# EOS-S3 register map
File version: 0.1
CPU: CM4 r0p1, selectable endian, MPU, FPU, 3 interrupt priority bits
Registers are 32-bit, read-write, reset 0x0 unless marked. A register's access mark holds for its fields unless they carry their own. Offsets are from the block's base; [hi:lo] are bit positions; {n}, {i} and the like mark numbered series.

## I2S_Slave
Base 0x4000B000
0x00 IER — I2S Enable Register
  [0] IEN — DW_apb_i2s_enable. A disable on this bit overrides any other block or channel enables and flushes all FIFOs.
    0=disable (Enable DW_APB_I2S.); 1=enable (Disable DW_APB_I2S.)
0x08 ITER — I2S Transmitter Block Enable Register
  [0] TXEN — Transmitter block enable. A disable on this bit overrides any individual transmit channel enables.
    0=Disable the transmitter; 1=Enable the transmitter
0x18 TXFFR — Transmitter Block FIFO Reset Register
  [0] TXFFR wo — Transmitter FIFO Reset. Writing a 1 to this register flushes all the TX FIFOs (this is a self clearing bit). The Transmitter Block must be disabled prior to writing this bit.
0x20 LTHR0 — Left Transmit Holding Register
  [31:0] LTHR0 wo — The left stereo data to be transmitted serially through the transmit channel output (sdox) is written through this register. Writing is a two-stage process: (1) A write to this register passes the left stereo sample to the transmitter. (2) This MUST be followed by writing the right stereo sample to the RTHRx register. Data should only be written to the FIFO when it is not full. Any attempt to write to a full FIFO results in that data being lost and an overrun interrupt being generated.
0x24 RTHR0 — Right Transmit Holding Register
  [31:0] RTHR0 wo — The right stereo data to be transmitted serially through the transmit channel output (sdox) is written through this register. Writing is a two-stage process: (1) A left stereo sample MUST first be written to the LTHRx register. (2) A write to this register passes the right stereo sample to the transmitter. Data should only be written to the FIFO when it is not full. Any attempt to write to a full FIFO results in that data being lost and an overrun interrupt being generated.
0x2C TER0 reset 0x1 — Transmit Enable Register
  [0] TXCHEN0 — Transmit channel enable. This bit enables/disables a transmit channel, independently of all other channels. On enable, the channel begins transmitting on the next left stereo cycle. A global disable of DW_apb_i2s (IER[0] = 0) or Transmitter block (ITER[0] =0) overrides this value.
    0=Disable the transmit channel; 1=Enable the transmit channel
0x34 TCR0 reset 0x2 — Transmit Configuration Register
  [2:0] WLEN — These bits are used to program the data resolution of the transmitter and ensures the MSB of the data is transmitted first. Programmed resolution must be less than or equal to `I2S_TX_WORDSIZE_x`. If the selected resolution is greater than `I2S_TX_WORDSIZE_x`, the transmit channel defaults back to `I2S_TX_WORDSIZE_RESET_x` value. The channel must be disabled prior to any changes in this value (`TERx[0] = 0`).
    0=Ignore word length; 1=word_12bit (12 bit resolution.); 2=word_16bit (16 bit resolution.); 3=word_20bit (20 bit resolution.); 4=word_24bit (24 bit resolution.); 5=word_32bit (32 bit resolution.)
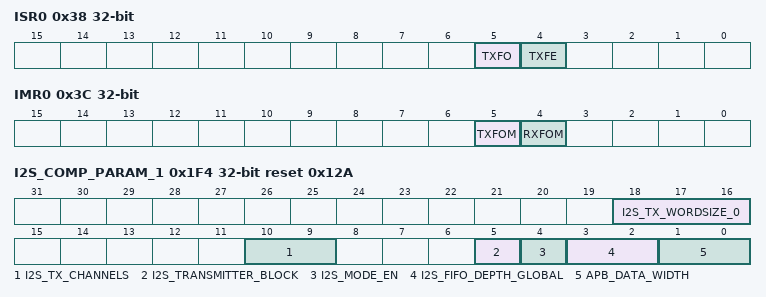
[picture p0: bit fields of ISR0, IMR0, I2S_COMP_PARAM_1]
0x38 ISR0 — Interrupt Status Register
  [5] TXFO ro — Status of Data Overrun interrupt for the TX channel. Attempt to write to full TX FIFO. Dependencies: I2S_TX_CHANNELS > x, where x is the number of transmit channel.
    0=trigger_not_reached (Trigger level not reached.); 1=trigger_reached (Trigger level reached.)
  [4] TXFE ro — Status of Transmit Empty Trigger interrupt. TX FIFO is empty.
    0=write_valid (TX FIFO write valid.); 1=write_overrun (TX FIFO write overrun.)
0x3C IMR0 — Interrupt Mask Register
  [5] TXFOM — Masks TX FIFO Empty interrupt.
    0=Unmask the interrupt; 1=Mask the interrupt
  [4] RXFOM — Masks TX FIFO Overrun interrupt.
    0=Unmask the interrupt; 1=Mask the interrupt
0x44 TOR0 — Transmit Overrun Register
  [0] TXCHO ro — Read this bit to clear the TX FIFO Data Overrun interrupt.
0x4C TFCR0 reset 0x4 — Transmit FIFO Configuration Register
  [3:0] TXCHET — Transmit Channel Empty Trigger. These bits program the trigger level in the TX FIFO at which the Empty Threshold Reached Interrupt is generated. Trigger Level = `TXCHET` `TXCHET` values: 0 to (`I2S_TX_FIFO_x – 1`) If an illegal value is programmed, these bits saturate to `(I2S_TX_FIFO_x – 1)`. The channel must be disabled prior to any changes in this value (that is, `TERx[0] = 0`).
0x54 TFF0 — Transmit FIFO Flush
  [0] TXCHFR wo — Transmit Channel FIFO Reset. Writing a 1 to this register flushes channel’s TX FIFO. (This is a self clearing bit.) TX channel or block must be disabled prior to writing to this bit.
0x1C8 TXDMA — Transmitter Block DMA Register
  [31:0] TXDMA wo — Transmitter Block DMA Register. This register can be used to cycle repeatedly through the enabled Transmit channels (from lowest numbered to highest) to allow writing of stereo data pairs
0x1CC RTXDMA — Reset Transmitter Block DMA Register
  [0] RTXDMA wo — Reset Transmitter Block DMA Register. Writing a 1 to this self-clearing register resets the TXDMA register mid-cycle to point to the lowest enabled Transmit channel. NOTE: This register has no effect in the middle of a stereo pair write (such as,when left stereo data has been written but not right stereo data)
0x1F4 I2S_COMP_PARAM_1 reset 0x12A — Component Parameter Register 1
  [18:16] I2S_TX_WORDSIZE_0 ro — Indicates the wordsize of I2S TX packets
    0=x12bit (TX configured with 12bit wordsize); 1=x16bit (TX configured with 16bit wordsize); 2=x20bit (TX configured with 20bit wordsize); 3=x24bit (TX configured with 24bit wordsize); 4=x32bit (TX configured with 32bit wordsize)
  [10:9] I2S_TX_CHANNELS ro — Indicates how many I2S TX channels are active
    {v}=x{v+1}_channel ({v+1} TX channel.) (v=0..3)
  [5] I2S_TRANSMITTER_BLOCK ro
  [4] I2S_MODE_EN ro — Enabled mode for the I2S peripheral
    0=slave (I2S operating in slave mode.); 1=master (I2S operating in master mode)
  [3:2] I2S_FIFO_DEPTH_GLOBAL ro — Indicates the value of I2S_FIFO_DEPTH_GLOBAL
    0=depth_2 (I2S_FIFO_DEPTH_GLOBAL equals 2); 1=depth_4 (I2S_FIFO_DEPTH_GLOBAL equals 4); 2=depth_8 (I2S_FIFO_DEPTH_GLOBAL equals 8); 3=depth_16 (I2S_FIFO_DEPTH_GLOBAL equals 16)
  [1:0] APB_DATA_WIDTH ro — Data width of the APB
    0=x8bit (APB data width is 8 bit); 1=x16bit (APB data width is 16 bit); 2=x32bit (APB data width is 32 bit)
0x1F8 I2S_COMP_VERSION reset 0x3130382A — Component version of the I2S peripheral.
  [31:0] I2S_COMP_VERSION ro
0x1FC I2S_COMP_TYPE reset 0x445701A0 — Component type of the I2S peripheral.
  [31:0] I2S_COMP_TYPE ro
0x3F8 I2S_STEREO_EN — Sound channel mode (mono or stereo)
  [0] I2S_STEREO_EN — Select between mono or stereo modes
    0=mono (Configure I2S for monoaural sound reproduction); 1=stereo (Configure I2S for stereo sound reproduction)
